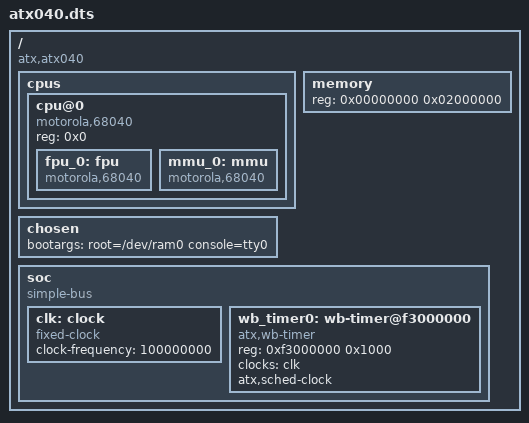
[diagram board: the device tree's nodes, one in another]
/dts-v1/;

/ {
	compatible = "atx,atx040";
	#address-cells = <1>;
	#size-cells = <1>;

	cpus {
		#address-cells = <1>;
		#size-cells = <0>;

		cpu@0 {
			device_type = "cpu";
			compatible = "motorola,68040";
			reg = <0x0>;

			fpu_0: fpu {
				compatible = "motorola,68040";
			};

			mmu_0: mmu {
				compatible = "motorola,68040";
			};
		};
	};


	chosen {
		bootargs = "root=/dev/ram0 console=tty0";
	};

	memory {
		device_type = "memory";
		reg = <0x00000000 0x02000000>;
	};

	soc {
		compatible = "simple-bus";
		#address-cells = <1>;
		#size-cells = <1>;
		ranges;

		clk: clock {
			compatible = "fixed-clock";
			#clock-cells = <0>;
			clock-frequency = <100000000>;
		};

		wb_timer0: wb-timer@f3000000 {
			status = "okay";
			compatible = "atx,wb-timer";
			reg = <0xf3000000 0x1000>;
			clocks = <&clk>;
			atx,sched-clock;
		};
	};
};
